# L4PER_CM2 register map
Vendor: Texas Instruments
Peripheral module from a debugger description file (folder omap4460).
Registers are 32-bit, access per field, reset 0x30000 unless marked. A register's access mark holds for its fields unless they carry their own. Offsets are as the file gives them; lines under a group give offsets from that group; [hi:lo] are bit positions; {n}, {i} and the like mark numbered series; 'fields as' and 'values as' point back to an identical list; <NAME> marks a mode.

## L4PER_CM2
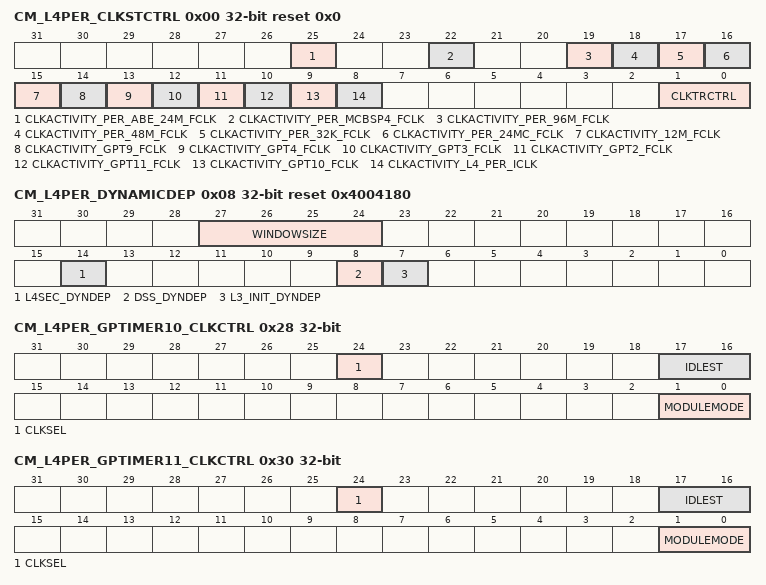
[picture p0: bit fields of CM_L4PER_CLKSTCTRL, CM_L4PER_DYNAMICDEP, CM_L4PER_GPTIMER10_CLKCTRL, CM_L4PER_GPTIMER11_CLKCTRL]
0x00 CM_L4PER_CLKSTCTRL reset 0x0 — This register enables the domain power state transition. It controls the hardware supervised domain power state transition between ON-ACTIVE and ON-INACTIVE states. It also holds 1 status bit per clock input of the domain.
  [25] CLKACTIVITY_PER_ABE_24M_FCLK ro — This field indicates the state of the PER_ABE_24M_FCLK clock in the domain. [warm reset insensitive]
    0=CLKACTIVITY_PER_ABE_24M_FCLK_0_r (Corresponding clock is definitely gated); 1=CLKACTIVITY_PER_ABE_24M_FCLK_1_r (Corresponding clock is running or gating/ungating transition is ongoing)
  [22] CLKACTIVITY_PER_MCBSP4_FCLK ro — This field indicates the state of the PER_MCBSP4_FCLK clock in the domain. [warm reset insensitive]
    0=CLKACTIVITY_PER_MCBSP4_FCLK_0_r (Corresponding clock is definitely gated); 1=CLKACTIVITY_PER_MCBSP4_FCLK_1_r (Corresponding clock is running or gating/ungating transition is ongoing)
  [19] CLKACTIVITY_PER_96M_FCLK ro — This field indicates the state of the PER_96M_FCLK clock in the domain. [warm reset insensitive]
    0=CLKACTIVITY_PER_96M_FCLK_0_r (Corresponding clock is definitely gated); 1=CLKACTIVITY_PER_96M_FCLK_1_r (Corresponding clock is running or gating/ungating transition is ongoing)
  [18] CLKACTIVITY_PER_48M_FCLK ro — This field indicates the state of the PER_48M_FCLK clock in the domain. [warm reset insensitive]
    0=CLKACTIVITY_PER_48M_FCLK_0_r (Corresponding clock is definitely gated); 1=CLKACTIVITY_PER_48M_FCLK_1_r (Corresponding clock is running or gating/ungating transition is ongoing)
  [17] CLKACTIVITY_PER_32K_FCLK ro — This field indicates the state of the PER_32K_FCLK clock in the domain. [warm reset insensitive]
    0=CLKACTIVITY_PER_32K_FCLK_0_r (Corresponding clock is definitely gated); 1=CLKACTIVITY_PER_32K_FCLK_1_r (Corresponding clock is running or gating/ungating transition is ongoing)
  [16] CLKACTIVITY_PER_24MC_FCLK ro — This field indicates the state of the PER_24MC_FCLK clock in the domain. [warm reset insensitive]
    0=CLKACTIVITY_PER_24MC_FCLK_0_r (Corresponding clock is definitely gated); 1=CLKACTIVITY_PER_24MC_FCLK_1_r (Corresponding clock is running or gating/ungating transition is ongoing)
  [15] CLKACTIVITY_12M_FCLK ro — This field indicates the state of the FUNC_12M_FCLK clock in the domain. [warm reset insensitive]
    0=CLKACTIVITY_12M_FCLK_0_r (Corresponding clock is definitely gated); 1=CLKACTIVITY_12M_FCLK_1_r (Corresponding clock is running or gating/ungating transition is ongoing)
  [14] CLKACTIVITY_GPT9_FCLK ro — This field indicates the state of the DMT9_FCLK clock in the domain. [warm reset insensitive]
    0=CLKACTIVITY_GPT9_FCLK_0_r (Corresponding clock is definitely gated); 1=CLKACTIVITY_GPT9_FCLK_1_r (Corresponding clock is running or gating/ungating transition is ongoing)
  [13] CLKACTIVITY_GPT4_FCLK ro — This field indicates the state of the DMT4_FCLK clock in the domain. [warm reset insensitive]
    0=CLKACTIVITY_GPT4_FCLK_0_r (Corresponding clock is definitely gated); 1=CLKACTIVITY_GPT4_FCLK_1_r (Corresponding clock is running or gating/ungating transition is ongoing)
  [12] CLKACTIVITY_GPT3_FCLK ro — This field indicates the state of the DMT3_FCLK clock in the domain. [warm reset insensitive]
    0=CLKACTIVITY_GPT3_FCLK_0_r (Corresponding clock is definitely gated); 1=CLKACTIVITY_GPT3_FCLK_1_r (Corresponding clock is running or gating/ungating transition is ongoing)
  [11] CLKACTIVITY_GPT2_FCLK ro — This field indicates the state of the DMT2_FCLK clock in the domain. [warm reset insensitive]
    0=CLKACTIVITY_GPT2_FCLK_0_r (Corresponding clock is definitely gated); 1=CLKACTIVITY_GPT2_FCLK_1_r (Corresponding clock is running or gating/ungating transition is ongoing)
  [10] CLKACTIVITY_GPT11_FCLK ro — This field indicates the state of the DMT11_FCLK clock in the domain. [warm reset insensitive]
    0=CLKACTIVITY_GPT11_FCLK_0_r (Corresponding clock is definitely gated); 1=CLKACTIVITY_GPT11_FCLK_1_r (Corresponding clock is running or gating/ungating transition is ongoing)
  [9] CLKACTIVITY_GPT10_FCLK ro — This field indicates the state of the DMT10_FCLK clock in the domain. [warm reset insensitive]
    0=CLKACTIVITY_GPT10_FCLK_0_r (Corresponding clock is definitely gated); 1=CLKACTIVITY_GPT10_FCLK_1_r (Corresponding clock is running or gating/ungating transition is ongoing)
  [8] CLKACTIVITY_L4_PER_ICLK ro — This field indicates the state of the L4_PER_GICLK clock in the domain. [warm reset insensitive]
    0=CLKACTIVITY_L4_PER_ICLK_0_r (Corresponding clock is definitely gated); 1=CLKACTIVITY_L4_PER_ICLK_1_r (Corresponding clock is running or gating/ungating transition is ongoing)
  [1:0] CLKTRCTRL rw — Controls the clock state transition of the L4PER clock domain.
    0=NO_SLEEP: Sleep transition cannot be initiated. Wakeup transition may however occur.; 1=SW_SLEEP: Start a software forced sleep transition on the domain; 2=SW_WKUP: Start a software forced wake-up transition on the domain; 3=HW_AUTO: Automatic transition is enabled. Sleep and wakeup transition are based upon hardware conditions.
0x08 CM_L4PER_DYNAMICDEP access not given reset 0x4004180 — This register controls the dynamic domain dependencies from L4PER domain towards 'target' domains. It is relevant only for domain having INTERCONN master port(s).
  [27:24] WINDOWSIZE rw — Size of sliding window used to monitor INTRCONN interface activity for determination of auto-sleep feature. Time unit defined byCM_DYN_DEP_PRESCAL register.
  [14] L4SEC_DYNDEP ro — Dynamic dependency towards L4SEC clock domain
    1=L4SEC_DYNDEP_1_r (Dependency is enabled)
  [8] DSS_DYNDEP — Dynamic dependency towards DSS clock domain (access R Rreturns1s)
    1=DSS_DYNDEP_1_r (Dependency is enabled)
  [7] L3_INIT_DYNDEP — Dynamic dependency towards L3INIT clock domain (access R Rreturns1s)
    1=L3_INIT_DYNDEP_1_r (Dependency is enabled)
0x28 CM_L4PER_GPTIMER10_CLKCTRL — This register manages the DMTIMER10 clocks.
  [24] CLKSEL rw — Select the source of the functional clock
    0=Selects the SYS_CLK as the source; 1=Selects the 32KHz as the source
  [17:16] IDLEST ro — Module idle status. [warm reset insensitive]
    0=IDLEST_0_r (Module is fully functional, including INTRCONN); 1=IDLEST_1_r (Module is performing transition: wakeup, or sleep, or sleep abortion); 2=IDLEST_2_r (Module is in idle mode (only INTRCONN part). It is functional if using separate functional clock); 3=IDLEST_3_r (Module is disabled and cannot be accessed)
  [1:0] MODULEMODE rw — Control the way mandatory clocks are managed.
    0=Module is disable by software. Any INTRCONN access to module results in an error, except if resulting from a module wakeup (asynchronous wakeup).; 1=MODULEMODE_1_r (Reserved); 2=Module is explicitly enabled. Interface clock (if not used for functions) may be gated according to the clock domain state. Functional clocks are guarantied to stay present. As long as in this configuration, power domain sleep transition cannot happen.; 3=MODULEMODE_3_r (Reserved)
0x30 CM_L4PER_GPTIMER11_CLKCTRL — This register manages the DMTIMER11 clocks.
  fields as CM_L4PER_GPTIMER10_CLKCTRL
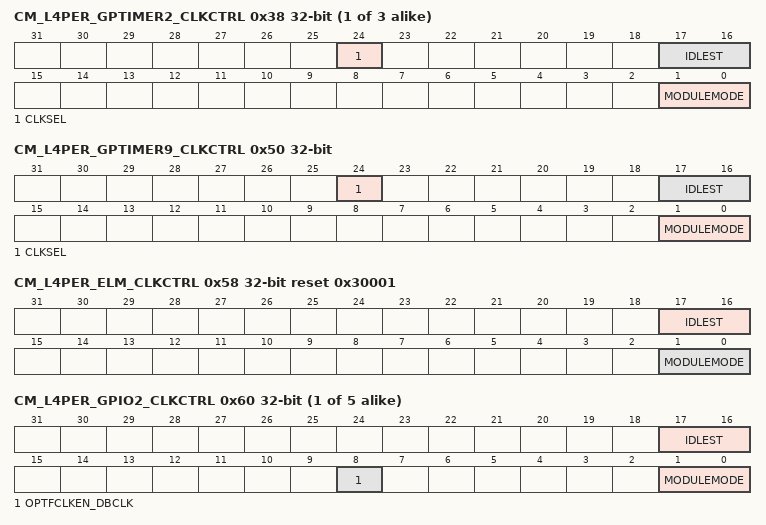
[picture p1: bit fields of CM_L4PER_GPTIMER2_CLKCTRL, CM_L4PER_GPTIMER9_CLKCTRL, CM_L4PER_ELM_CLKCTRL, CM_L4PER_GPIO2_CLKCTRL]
{0x28+8i} CM_L4PER_GPTIMER{i}_CLKCTRL (i=2..4) — This register manages the DMTIMER{i} clocks.
  fields as CM_L4PER_GPTIMER10_CLKCTRL
0x50 CM_L4PER_GPTIMER9_CLKCTRL — This register manages the DMTIMER9 clocks.
  fields as CM_L4PER_GPTIMER10_CLKCTRL
0x58 CM_L4PER_ELM_CLKCTRL access not given reset 0x30001 — This register manages the ELM clocks.
  [17:16] IDLEST ro — Module idle status. [warm reset insensitive]
    values as CM_L4PER_GPTIMER10_CLKCTRL.IDLEST
  [1:0] MODULEMODE — Control the way mandatory clocks are managed. (access R Rreturns)
    1=MODULEMODE_1_r (Module is managed automatically by hardware according to clock domain transition. A clock domain sleep transition put module into idle. A wakeup domain transition put it back into function. If CLKTRCTRL=3, any INTRCONN access to module is always granted. Module clocks may be gated according to the clock domain state.)
{0x50+8i} CM_L4PER_GPIO{i}_CLKCTRL (i=2..6) — This register manages the GPIO{i} clocks.
  [17:16] IDLEST ro — Module idle status. [warm reset insensitive]
    values as CM_L4PER_GPTIMER10_CLKCTRL.IDLEST
  [8] OPTFCLKEN_DBCLK rw — Optional functional clock control.
    0=Optional functional clock is disabled; 1=Optional functional clock is enabled
  [1:0] MODULEMODE rw — Control the way mandatory clocks are managed.
    0=Module is disable by software. Any INTRCONN access to module results in an error, except if resulting from a module wakeup (asynchronous wakeup).; 1=Module is managed automatically by hardware according to clock domain transition. A clock domain sleep transition put module into idle. A wakeup domain transition put it back into function. If CLKTRCTRL=3, any INTRCONN access to module is always granted. Module clocks may be gated according to the clock domain state.; 2=MODULEMODE_2_r (Reserved); 3=MODULEMODE_3_r (Reserved)
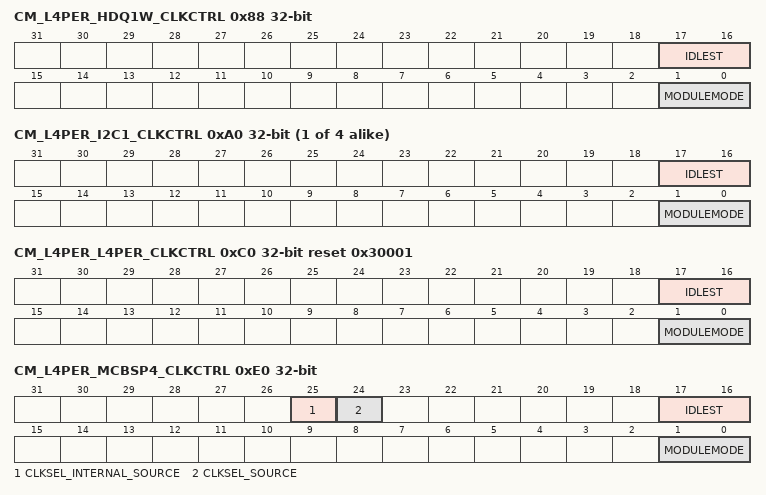
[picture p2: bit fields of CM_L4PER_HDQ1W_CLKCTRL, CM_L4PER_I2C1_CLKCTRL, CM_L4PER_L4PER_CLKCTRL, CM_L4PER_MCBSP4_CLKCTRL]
0x88 CM_L4PER_HDQ1W_CLKCTRL — This register manages the HDQ1W clocks.
  [17:16] IDLEST ro — Module idle status. [warm reset insensitive]
    values as CM_L4PER_GPTIMER10_CLKCTRL.IDLEST
  [1:0] MODULEMODE rw — Control the way mandatory clocks are managed.
    values as CM_L4PER_GPTIMER10_CLKCTRL.MODULEMODE
{0x98+8i} CM_L4PER_I2C{i}_CLKCTRL (i=1..4) — This register manages the I2C{i} clocks.
  fields as CM_L4PER_HDQ1W_CLKCTRL
0xC0 CM_L4PER_L4PER_CLKCTRL access not given reset 0x30001 — This register manages the L4PER clocks.
  fields as CM_L4PER_ELM_CLKCTRL
0xE0 CM_L4PER_MCBSP4_CLKCTRL — This register manages the MCBSP4 clocks.
  [25] CLKSEL_INTERNAL_SOURCE rw — Selects the internal clock to be used as the functional clock in case CLKSEL_SOURCE selects the internal clock source as the functional clock source.
    0=96MHz clock derived from DPLL_PER is selected; 1=98MHz clock derived from DPLL_ABE is selected
  [24] CLKSEL_SOURCE rw — Selects the source of the functional clock between, internal source and CLKS pad. The switching between the clocks is not guaranteed to be glitchless.
    0=Functional clock is sourced from an internal clock; 1=Functional clock is sourced from CLKS pad
  [17:16] IDLEST ro — Module idle status. [warm reset insensitive]
    values as CM_L4PER_GPTIMER10_CLKCTRL.IDLEST
  [1:0] MODULEMODE rw — Control the way mandatory clocks are managed.
    values as CM_L4PER_GPTIMER10_CLKCTRL.MODULEMODE
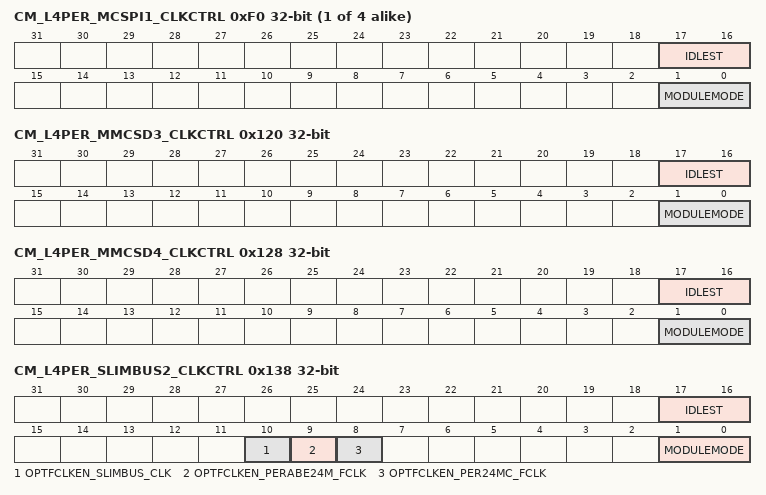
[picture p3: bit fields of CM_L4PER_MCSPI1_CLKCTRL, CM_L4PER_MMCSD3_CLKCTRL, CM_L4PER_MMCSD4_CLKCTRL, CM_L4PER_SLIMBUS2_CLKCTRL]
{0xE8+8i} CM_L4PER_MCSPI{i}_CLKCTRL (i=1..4) — This register manages the MCSPI{i} clocks.
  fields as CM_L4PER_HDQ1W_CLKCTRL
0x120 CM_L4PER_MMCSD3_CLKCTRL — This register manages the MMCSD3 clocks.
  fields as CM_L4PER_HDQ1W_CLKCTRL
0x128 CM_L4PER_MMCSD4_CLKCTRL — This register manages the MMCSD4 clocks.
  fields as CM_L4PER_HDQ1W_CLKCTRL
0x138 CM_L4PER_SLIMBUS2_CLKCTRL — This register manages the SLIMBUS2 clocks.
  [17:16] IDLEST ro — Module idle status. [warm reset insensitive]
    values as CM_L4PER_GPTIMER10_CLKCTRL.IDLEST
  [10] OPTFCLKEN_SLIMBUS_CLK rw — Optional functional clock control.
    values as CM_L4PER_GPIO2_CLKCTRL.OPTFCLKEN_DBCLK
  [9] OPTFCLKEN_PERABE24M_FCLK rw — Optional functional clock control for PER_ABE_24M_FCLK clock.
    values as CM_L4PER_GPIO2_CLKCTRL.OPTFCLKEN_DBCLK
  [8] OPTFCLKEN_PER24MC_FCLK rw — Optional functional clock control for PER_24MC_FCLK clock.
    values as CM_L4PER_GPIO2_CLKCTRL.OPTFCLKEN_DBCLK
  [1:0] MODULEMODE rw — Control the way mandatory clocks are managed.
    values as CM_L4PER_GPTIMER10_CLKCTRL.MODULEMODE
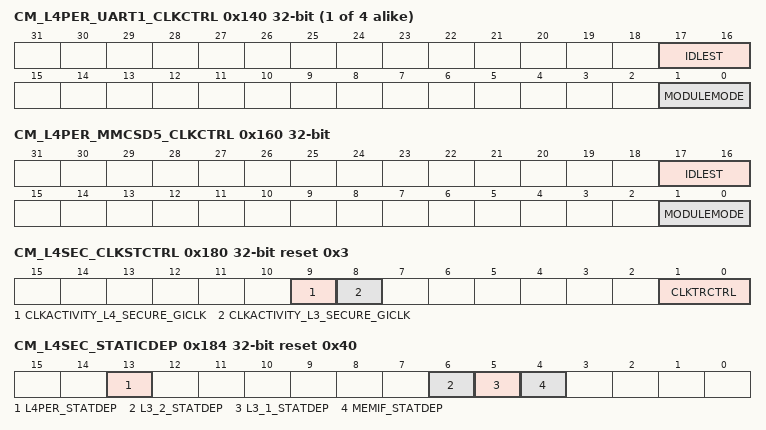
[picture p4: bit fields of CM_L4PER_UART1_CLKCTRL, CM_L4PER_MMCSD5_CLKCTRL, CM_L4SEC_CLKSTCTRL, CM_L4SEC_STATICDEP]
{0x138+8i} CM_L4PER_UART{i}_CLKCTRL (i=1..4) — This register manages the UART{i} clocks.
  fields as CM_L4PER_HDQ1W_CLKCTRL
0x160 CM_L4PER_MMCSD5_CLKCTRL — This register manages the MMCSD5 clocks.
  fields as CM_L4PER_HDQ1W_CLKCTRL
0x180 CM_L4SEC_CLKSTCTRL reset 0x3 — This register enables the domain power state transition. It controls the hardware-supervised domain power state transition between ON-ACTIVE and ON-INACTIVE states. It also holds one status bit per clock input of the domain.
  [9] CLKACTIVITY_L4_SECURE_GICLK ro — This field indicates the state of the L4_SECURE_GICLK clock in the domain.
    0=CLKACTIVITY_L4_SECURE_GICLK_0_r (Corresponding clock is definitely gated); 1=CLKACTIVITY_L4_SECURE_GICLK_1_r (Corresponding clock is running or gating/ungating transition is on-going)
  [8] CLKACTIVITY_L3_SECURE_GICLK ro — This field indicates the state of the L3_SECURE_GICLK clock in the domain.
    0=CLKACTIVITY_L3_SECURE_GICLK_0_r (Corresponding clock is definitely gated); 1=CLKACTIVITY_L3_SECURE_GICLK_1_r (Corresponding clock is running or gating/ungating transition is on-going)
  [1:0] CLKTRCTRL rw — Controls the clock state transition of the L4SEC clock domain.
    values as CM_L4PER_CLKSTCTRL.CLKTRCTRL
0x184 CM_L4SEC_STATICDEP reset 0x40 — This register controls the static domain dependencies from L4SEC domain towards 'target' domains. It is relevant only for domain having system initiator(s).
  [13] L4PER_STATDEP rw — Static dependency towards L4PER clock domain
    0=Dependency is disabled; 1=Dependency is enabled
  [6] L3_2_STATDEP ro — Static dependency towards L3_2 clock domain
    1=L3_2_STATDEP_1_r (Dependency is enabled)
  [5] L3_1_STATDEP rw — Static dependency towards L3_1 clock domain
    0=Dependency is disabled; 1=Dependency is enabled
  [4] MEMIF_STATDEP rw — Static dependency towards MEMIF clock domain
    0=Dependency is disabled; 1=Dependency is enabled
0x188 CM_L4SEC_DYNAMICDEP ro reset 0x0 — This register controls the dynamic domain dependencies from L4SEC domain towards 'target' domains. It is relevant only for domain having OCP master port(s).
  [6] L3_2_DYNDEP — Dynamic dependency towards L3_2 clock domain
    0=L3_2_DYNDEP_0_r (Dependency is disabled)
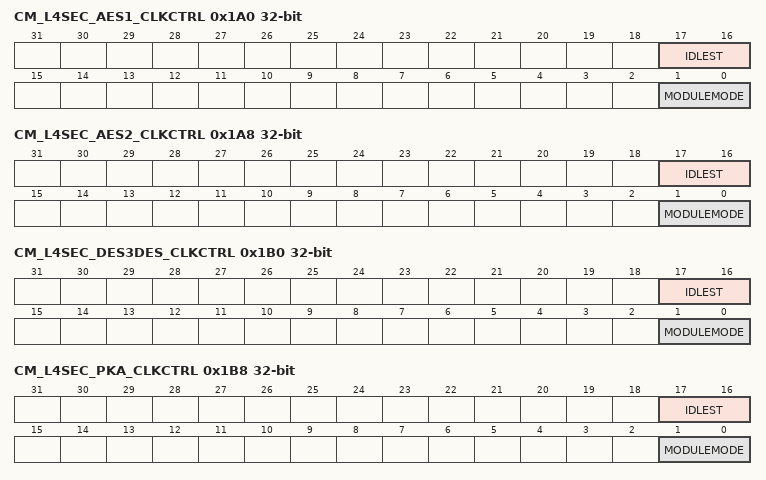
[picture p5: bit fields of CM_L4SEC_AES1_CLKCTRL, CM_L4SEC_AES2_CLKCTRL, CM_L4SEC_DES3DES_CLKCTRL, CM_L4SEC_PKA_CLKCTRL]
0x1A0 CM_L4SEC_AES1_CLKCTRL — This register manages the AES1 clocks.
  [17:16] IDLEST ro — Module idle status. [warm reset insensitive]
    0=IDLEST_0_r (Module is fully functional, including OCP); 1=IDLEST_1_r (Module is performing transition: wakeup, or sleep, or sleep abortion); 2=IDLEST_2_r (Module is in Idle mode (only OCP part). It is functional if using separate functional clock); 3=IDLEST_3_r (Module is disabled and cannot be accessed)
  [1:0] MODULEMODE rw — Control the way mandatory clocks are managed.
    0=Module is disabled by SW. Any OCP access to module results in an error, except if resulting from a module wakeup (asynchronous wakeup).; 1=MODULEMODE_1_r (Reserved); 2=Module is explicitly enabled. Interface clock (if not used for functions) may be gated according to the clock domain state. Functional clocks are guaranteed to stay present. As long as in this configuration, power domain sleep transition cannot happen.; 3=MODULEMODE_3_r (Reserved)
0x1A8 CM_L4SEC_AES2_CLKCTRL — This register manages the AES2 clocks.
  fields as CM_L4SEC_AES1_CLKCTRL
0x1B0 CM_L4SEC_DES3DES_CLKCTRL — This register manages the DES3DES clocks.
  fields as CM_L4SEC_AES1_CLKCTRL
0x1B8 CM_L4SEC_PKA_CLKCTRL — This register manages the PKA clocks.
  fields as CM_L4SEC_AES1_CLKCTRL
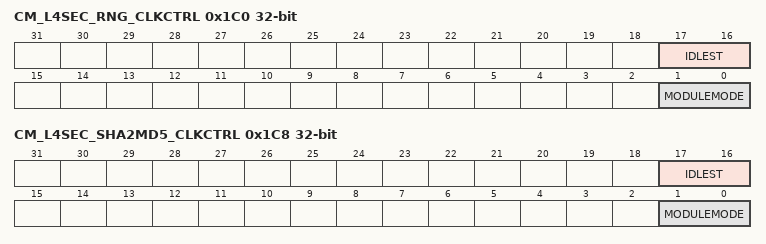
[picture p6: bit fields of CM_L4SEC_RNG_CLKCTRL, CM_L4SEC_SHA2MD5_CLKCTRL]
0x1C0 CM_L4SEC_RNG_CLKCTRL — This register manages the RNG clocks.
  [17:16] IDLEST ro — Module idle status. [warm reset insensitive]
    values as CM_L4SEC_AES1_CLKCTRL.IDLEST
  [1:0] MODULEMODE rw — Control the way mandatory clocks are managed.
    0=Module is disabled by SW. Any OCP access to module results in an error, except if resulting from a module wakeup (asynchronous wakeup).; 1=Module is managed automatically by HW according to clock domain transition. A clock domain sleep transition put module into idle. A wakeup domain transition put it back into function. If CLKTRCTRL=3, any OCP access to module is always granted. Module clocks may be gated according to the clock domain state.; 2=MODULEMODE_2_r (Reserved); 3=MODULEMODE_3_r (Reserved)
0x1C8 CM_L4SEC_SHA2MD5_CLKCTRL — This register manages the SHA2MD5 clocks.
  fields as CM_L4SEC_AES1_CLKCTRL
